# PRU_ICSS_MDIO register map
Vendor: Texas Instruments
Peripheral module from a debugger description file (folder am335x).
Registers are 32-bit, access not given, no defined reset value unless marked. A register's access mark holds for its fields unless they carry their own. Offsets are as the file gives them; lines under a group give offsets from that group; [hi:lo] are bit positions; {n}, {i} and the like mark numbered series; 'fields as' and 'values as' point back to an identical list; <NAME> marks a mode.

## MDIO
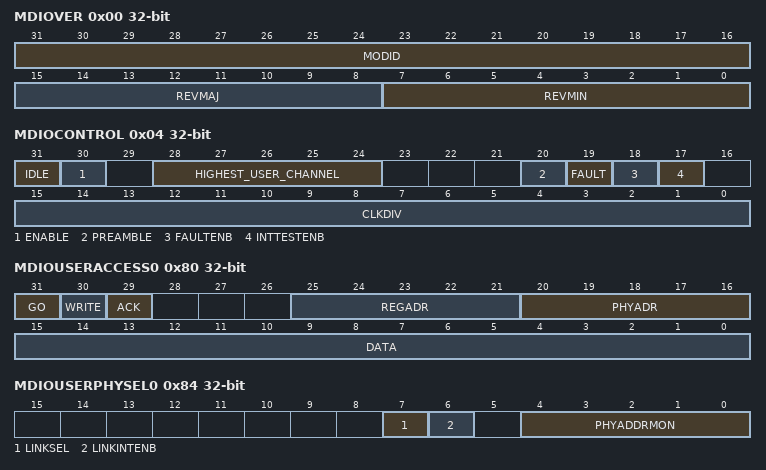
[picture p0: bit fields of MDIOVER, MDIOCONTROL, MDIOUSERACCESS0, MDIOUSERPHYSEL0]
0x00 MDIOVER ro
  [31:16] MODID — Identifies type of peripheral.
  [15:8] REVMAJ — Management interface module major revision value.
  [7:0] REVMIN — Management interface module minor revision value.
0x04 MDIOCONTROL
  [31] IDLE ro — MDIO state machine IDLE. Set to 1 when the state machine is in the idle state.
  [30] ENABLE rw — Enable control. If the MDIO state machine is active at the time it is disabled, it will complete the current operation before halting and setting the idle bit. If using byte access, the enable bit has to be the last bit written in this register.
  [28:24] HIGHEST_USER_CHANNEL ro — Highest user channel. This field specifies the highest user access channel that is available in the module and is currently set to 1. This implies that the MDIOUSERACCESS1 register is the highest available user access channel.
  [20] PREAMBLE rw — Preamble disable.
  [19] FAULT — Fault indicator. This bit is set to 1 if the MDIO pins fail to read back what the device is driving onto them. This indicates a physical layer fault and the module state machine is reset. Writing a 1 to it clears this bit. (access R/WC)
  [18] FAULTENB rw — Fault detect enable. This bit has to be set to 1 to enable the physical layer fault detection.
  [17] INTTESTENB rw — Interrupt test enable. This bit can be set to 1 to enable the host to set the USERINT and LINKINT bits for test purposes.
  [15:0] CLKDIV rw — Clock divider. This field specifies the division ratio between CLK and the frequency of MDCLK. MDCLK is disabled when clkdiv is set to 0. MDCLK frequency = clk frequency/(clkdiv+1).
0x08 MDIOALIVE
  [31:0] ALIVE — MDIO alive. Each of the 32 bits of this register is set if the most recent access to the PHY with address corresponding to the register bit number was acknowledged by the PHY, the bit is reset if the PHY fails to acknowledge the access. Both the user and polling accesses to a PHY will cause the corresponding alive bit to be updated. The alive bits are only meant to be used to give an indication of the presence or not of a PHY with the corresponding address. Writing a 1 to any bit will clear it, writing a 0 has no effect. (access R/WC)
0x0C MDIOLINK ro
  [31:0] LINK — MDIO link state. This register is updated after a read of the Generic Status Register of a PHY. The bit is set if the PHY with the corresponding address has link and the PHY acknowledges the read transaction. The bit is reset if the PHY indicates it does not have link or fails to acknowledge the read transaction. Writes to the register have no effect. In addition, the status of the two PHYs specified in the MDIOUSERPHYSEL registers can be determined using the MLINK input pins. This is determined by the LINKSEL bit in the MDIOUSERPHYSEL register.
0x10 MDIOLINKINTRAW
  [1:0] LINKINTRAW — MDIO link change event, raw value. When asserted 1, a bit indicates that there was an MDIO link change event (that is, change in the MDIOLINK register) corresponding to the PHY address in the MDIOUSERPHYSEL register. LINKINTRAW[0] and LINKINTRAW[1] correspond to MDIOUSERPHYSEL0 and MDIOUSERPHYSEL1, respectively. Writing a 1 will clear the event and writing 0 has no effect. If the INTTESTENB bit in the MDIOCONTROL register is set, the host may set the LINKINTRAW bits to a 1. This mode may be used for test purposes. (access R/WC)
0x14 MDIOLINKINTMASKED
  [1:0] LINKINTMASKED — MDIO link change interrupt, masked value. When asserted 1, a bit indicates that there was an MDIO link change event (that is, change in the MDIO Link register) corresponding to the PHY address in the MDIOUSERPHYSEL register and the corresponding LINKINTENB bit was set. LINKINTMASKED[0] and LINKINTMASKED[1] correspond to MDIOUSERPHYSEL0 and MDIOUSERPHYSEL1, respectively. Writing a 1 will clear the interrupt and writing 0 has no effect. If the INTTESTENB bit in the MDIOCONTROL register is set, the host may set the LINKINT bits to a 1. This mode may be used for test purposes. (access R/WC)
0x20 MDIOUSERINTRAW
  [1:0] USERINTRAW — Raw value of MDIO user command complete event for the MDIOUSERACCESS1 register through the MDIOUSERACCESS0 register, respectively. When asserted 1, a bit indicates that the previously scheduled PHY read or write command using that particular MDIOUSERACCESSn register has completed. Writing a 1 will clear the event and writing 0 has no effect. If the INTTESTENB bit in the MDIOCONTROL register is set, the host may set the USERINTRAW bits to a 1. This mode may be used for test purposes. (access R/WC)
0x24 MDIOUSERINTMASKED
  [1:0] USERINTMASKED — Masked value of MDIO user command complete interrupt for the MDIOUSERACCESS1 register through the MDIOUSERACCESS0 register, respectively. When asserted 1, a bit indicates that the previously scheduled PHY read or write command using that particular MDIOUSERACCESSn register has completed and the corresponding USERINTMASKSET bit is set to 1. Writing a 1 will clear the interrupt and writing 0 has no effect. If the INTTESTENB bit in the MDIOCONTROL register is set, the host may set the USERINTMASKED bits to a 1. This mode may be used for test purposes. (access R/WC)
0x28 MDIOUSERINTMASKSET
  [1:0] USERINTMASKSET — MDIO user interrupt mask set for USERINTMASKED, respectively. Writing a bit to 1 will enable MDIO user command complete interrupts for that particular MDIOUSERACCESSn register. MDIO user interrupt for a particular MDIOUSERACCESSn register is disabled if the corresponding bit is 0. Writing a 0 to this register has no effect. (access R/WC)
0x2C MDIOUSERINTMASKCLR
  [1:0] USERINTMASKCLEAR — MDIO user command complete interrupt mask clear for USERINTMASKED, respectively. Writing a bit to 1 will disable further user command complete interrupts for that particular MDIOUSERACCESSn register. Writing a 0 to this register has no effect. (access R/WC)
0x80 MDIOUSERACCESS0
  [31] GO — Go. Writing a 1 to this bit causes the MDIO state machine to perform an MDIO access when it is convenient for it to do so, this is not an instantaneous process. Writing a 0 to this bit has no effect. This bit is write able only if the MDIO state machine is enabled. This bit will self clear when the requested access has been completed. Any writes to the MDIOUSERACCESS0 register are blocked when the GO bit is 1. If byte access is being used, the GO bit should be written last. (access R/W/S)
  [30] WRITE rw — Write enable. Setting this bit to a 1 causes the MDIO transaction to be a register write, otherwise it is a register read.
  [29] ACK rw — Acknowledge. This bit is set if the PHY acknowledged the read transaction.
  [25:21] REGADR rw — Register address. Specifies the PHY register to be accessed for this transaction.
  [20:16] PHYADR rw — PHY address. Specifies the PHY to be accesses for this transaction.
  [15:0] DATA rw — User data. The data value read from or to be written to the specified PHY register.
0x84 MDIOUSERPHYSEL0 access per field
  [7] LINKSEL rw — Link status determination select. Set to 1 to determine link status using the MLINK pin. Default value is 0 which implies that the link status is determined by the MDIO state machine.
  [6] LINKINTENB rw — Link change interrupt enable. Set to 1 to enable link change status interrupts for PHY address specified in PHYADDRMON. Link change interrupts are disabled if this bit is set to 0.
  [4:0] PHYADDRMON rw — PHY address whose link status is to be monitored.
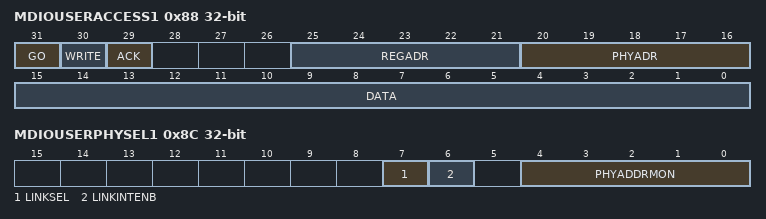
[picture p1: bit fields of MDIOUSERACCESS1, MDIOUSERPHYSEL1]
0x88 MDIOUSERACCESS1
  [31] GO — Writing a 1 to this bit causes the MDIO state machine to perform an MDIO access when it is convenient for it to do so, this is not an instantaneous process. Writing a 0 to this bit has no effect. This bit is write able only if the MDIO state machine is enabled. This bit will self clear when the requested access has been completed. Any writes to the MDIOUSERACCESS0 register are blocked when the GO bit is 1. If byte access is being used, the GO bit should be written last. (access R/W/S)
  [30] WRITE rw — Write enable. Setting this bit to a 1 causes the MDIO transaction to be a register write, otherwise it is a register read.
  [29] ACK rw — Acknowledge. This bit is set if the PHY acknowledged the read transaction.
  [25:21] REGADR rw — Register address; specifies the PHY register to be accessed for this transaction.
  [20:16] PHYADR rw — PHY address; specifies the PHY to be accesses for this transaction.
  [15:0] DATA rw — User data. The data value read from or to be written to the specified PHY register.
0x8C MDIOUSERPHYSEL1 access per field
  [7] LINKSEL rw — Link status determination select. Set to 1 to determine link status using the MLINK pin. Default value is 0 which implies that the link status is determined by the MDIO state machine.
  [6] LINKINTENB rw — Link change interrupt enable. Set to 1 to enable link change status interrupts for PHY address specified in PHYADDRMON. Link change interrupts are disabled if this bit is cleared to 0.
  [4:0] PHYADDRMON rw — PHY address whose link status is to be monitored.
